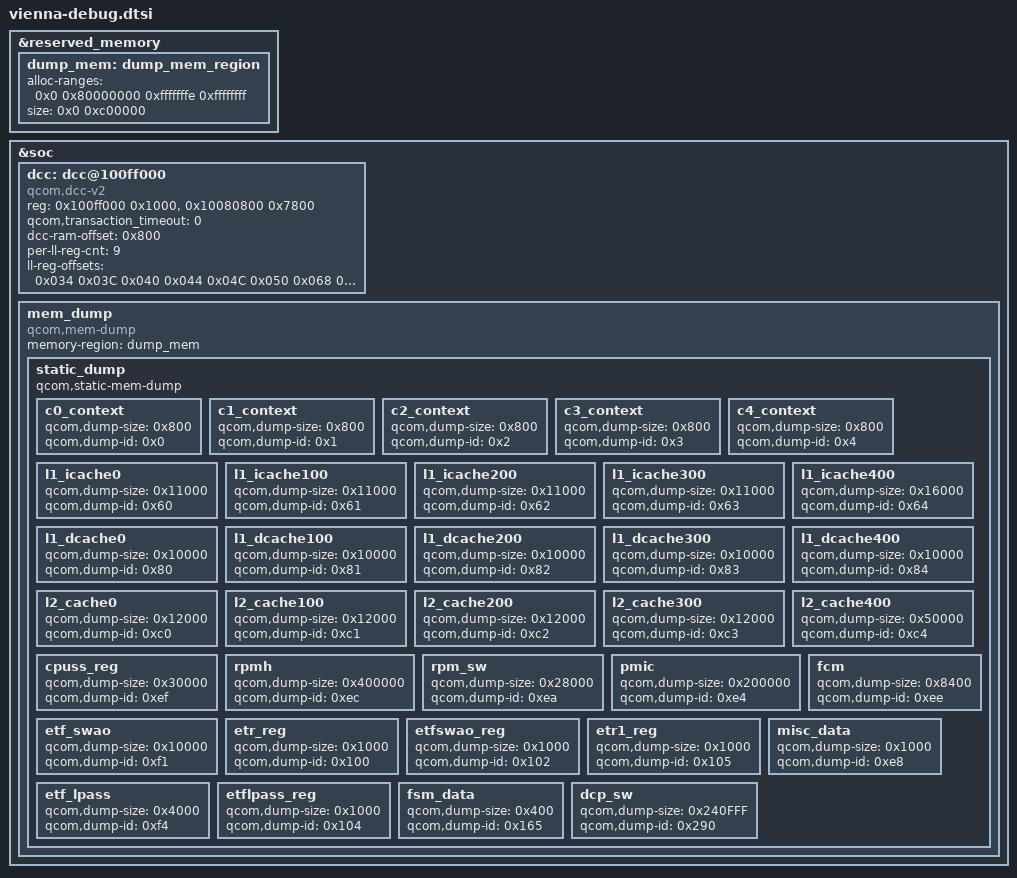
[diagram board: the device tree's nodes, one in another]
// SPDX-License-Identifier: BSD-3-Clause
/*
 * Copyright (c) Qualcomm Technologies, Inc. and/or its subsidiaries.
 */

#include <dt-bindings/soc/qcom,dcc_v2.h>

&reserved_memory {
	#address-cells = <2>;
	#size-cells = <2>;
	ranges;

	dump_mem: dump_mem_region {
		alloc-ranges = <0x0 0x80000000 0xfffffffe 0xffffffff>;
		size = <0x0 0xc00000>;
	};
};

&soc {
	dcc: dcc@100ff000 {
		compatible = "qcom,dcc-v2";
		reg = <0x100ff000 0x1000>,
		      <0x10080800 0x7800>;
		reg-names = "dcc-base", "dcc-ram-base";

		qcom,transaction_timeout = <0>;
		dcc-ram-offset = <0x800>;

		per-ll-reg-cnt = <9>;
		ll-reg-offsets = <0x034 0x03C 0x040 0x044 0x04C 0x050 0x068 0x06C 0x038
				  0x0B4 0x0BC 0x0C0 0x0C4 0x0CC 0x0D0 0x0E8 0x0EC 0x0B8
				  0x134 0x13C 0x140 0x144 0x14C 0x150 0x168 0x16C 0x138
				  0x1B4 0x1BC 0x1C0 0x1C4 0x1CC 0x1D0 0x1E8 0x1EC 0x1B8
				  0x234 0x23C 0x240 0x244 0x24C 0x250 0x268 0x26C 0x238
				  0x2B4 0x2BC 0x2C0 0x2C4 0x2CC 0x2D0 0x2E8 0x2EC 0x2B8
				  0x334 0x33C 0x340 0x344 0x34C 0x350 0x368 0x36C 0x338
				  0x3B4 0x3BC 0x3C0 0x3C4 0x3CC 0x3D0 0x3E8 0x3EC 0x3B8>;
	};

	mem_dump {
		compatible = "qcom,mem-dump";
		memory-region = <&dump_mem>;

		static_dump {
			qcom,static-mem-dump;

			c0_context {
					qcom,dump-size = <0x800>;
					qcom,dump-id = <0x0>;
			};

			c1_context {
					qcom,dump-size = <0x800>;
					qcom,dump-id = <0x1>;
			};

			c2_context {
					qcom,dump-size = <0x800>;
					qcom,dump-id = <0x2>;
			};

			c3_context {
					qcom,dump-size = <0x800>;
					qcom,dump-id = <0x3>;
			};

			c4_context {
					qcom,dump-size = <0x800>;
					qcom,dump-id = <0x4>;
			};

			l1_icache0 {
				qcom,dump-size = <0x11000>;
				qcom,dump-id = <0x60>;
			};

			l1_icache100 {
				qcom,dump-size = <0x11000>;
				qcom,dump-id = <0x61>;
			};

			l1_icache200 {
				qcom,dump-size = <0x11000>;
				qcom,dump-id = <0x62>;
			};

			l1_icache300 {
				qcom,dump-size = <0x11000>;
				qcom,dump-id = <0x63>;
			};

			l1_icache400 {
				qcom,dump-size = <0x16000>;
				qcom,dump-id = <0x64>;
				};

			l1_dcache0 {
				qcom,dump-size = <0x10000>;
				qcom,dump-id = <0x80>;
			};

			l1_dcache100 {
				qcom,dump-size = <0x10000>;
				qcom,dump-id = <0x81>;
			};

			l1_dcache200 {
				qcom,dump-size = <0x10000>;
				qcom,dump-id = <0x82>;
			};

			l1_dcache300 {
				qcom,dump-size = <0x10000>;
				qcom,dump-id = <0x83>;
			};

			l1_dcache400 {
				qcom,dump-size = <0x10000>;
				qcom,dump-id = <0x84>;
			};

			l2_cache0 {
				qcom,dump-size = <0x12000>;
				qcom,dump-id = <0xc0>;
			};

			l2_cache100 {
				qcom,dump-size = <0x12000>;
				qcom,dump-id = <0xc1>;
			};

			l2_cache200 {
				qcom,dump-size = <0x12000>;
				qcom,dump-id = <0xc2>;
			};

			l2_cache300 {
				qcom,dump-size = <0x12000>;
				qcom,dump-id = <0xc3>;
			};

			l2_cache400 {
				qcom,dump-size = <0x50000>;
				qcom,dump-id = <0xc4>;
			};

			cpuss_reg {
				qcom,dump-size = <0x30000>;
				qcom,dump-id = <0xef>;
			};

			rpmh {
				qcom,dump-size = <0x400000>;
				qcom,dump-id = <0xec>;
			};

			rpm_sw {
				qcom,dump-size = <0x28000>;
				qcom,dump-id = <0xea>;
			};

			pmic {
				qcom,dump-size = <0x200000>;
				qcom,dump-id = <0xe4>;
			};

			fcm {
				qcom,dump-size = <0x8400>;
				qcom,dump-id = <0xee>;
			};

			etf_swao {
				qcom,dump-size = <0x10000>;
				qcom,dump-id = <0xf1>;
			};

			etr_reg {
				qcom,dump-size = <0x1000>;
				qcom,dump-id = <0x100>;
			};

			etfswao_reg {
				qcom,dump-size = <0x1000>;
				qcom,dump-id = <0x102>;
			};

			etr1_reg {
				qcom,dump-size = <0x1000>;
				qcom,dump-id = <0x105>;
			};

			misc_data {
				qcom,dump-size = <0x1000>;
				qcom,dump-id = <0xe8>;
			};

			etf_lpass {
				qcom,dump-size = <0x4000>;
				qcom,dump-id = <0xf4>;
			};

			etflpass_reg {
				qcom,dump-size = <0x1000>;
				qcom,dump-id = <0x104>;
			};

			fsm_data {
				qcom,dump-size = <0x400>;
				qcom,dump-id = <0x165>;
			};

			dcp_sw {
				qcom,dump-size = <0x240FFF>;
				qcom,dump-id = <0x290>;
			};
		};
	};
};
